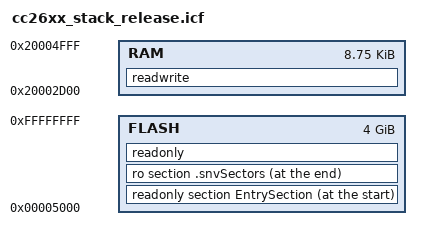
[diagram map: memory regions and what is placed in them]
/******************************************************************************

 @file  cc26xx_stack_release.icf

 @brief IAR ARM Linker Configuration File - BLE Stack

        Note: Code stack and heap are allocated by the Application/RTOS build.

        Imported Symbols
        Note: Linker defines are located in the IAR IDE project using
        --config_def in Options->Linker->Extra Options, or placed in
        Options->Linker-> Config->Configuration file symbol definitions.

        CCxxxx:             Device Name (e.g. CC2650). In order to define this
                            symbol, the tool chain requires that it be set to
                            a specific value, but in fact, the actual value does
                            not matter as it is not used in the linker control
                            file. The only way this symbol is used is based on
                            whether it is defined or not, not its actual value.
                            There are other linker symbols that do specifically
                            set their value to 1 to indicate R1, and 2 to
                            indicate R2, and these values are checked and do make
                            a difference. However, it would appear confusing if
                            the device name's value did not correspond to the
                            value set in other linker symbols. In order to avoid
                            this confusion, when the symbol is defined, it should
                            be set to the value of the device's ROM that it
                            corresponds so as to look and feel consistent. Please
                            note that a device name symbol should always be
                            defined to avoid side effects from default values
                            that may not be correct for the device being used.
        FLASH_ONLY_BUILD:   Build full BLE stack in flash only memory.
        FLASH_ROM_BUILD:    Build Flash portion of BLE stack to work with ROM
                            code.
        ROM_BUILD:          Build ROM portion of BLE stack.
        COMMON_ROM_BUILD:   Build of common ROM code.
        TEST_ROM_IN_FLASH:  Build ROM code in Flash memory to test.
        ICALL_STACK0_START: Start address of flash only and flash ROM builds.
        ICALL_RAM0_START:   Start address of RAM.

        Exported Symbols
        Note: Can be used as externs in C code.

        ROM_BASE_ADDR:        Location of start of ROM (where RT Init is
                              expected).
        RAM_BASE_ADDR:        Location of start of RAM (for ICall and JT
                              pointers).
        COMMON_RAM_BASE_ADDR: Location of start of RAM (for ICall and JT
                              pointers).
        PAGE_SIZE:            Size of Flash sector, in bytes.
        NUM_SNV_PAGES:        Number of sectors used for Simple NV.

 Group: WCS, BTS
 Target Device: cc13xx_cc26xx

 ******************************************************************************
 
 Copyright (c) 2013-2022, Texas Instruments Incorporated
 All rights reserved.

 Redistribution and use in source and binary forms, with or without
 modification, are permitted provided that the following conditions
 are met:

 *  Redistributions of source code must retain the above copyright
    notice, this list of conditions and the following disclaimer.

 *  Redistributions in binary form must reproduce the above copyright
    notice, this list of conditions and the following disclaimer in the
    documentation and/or other materials provided with the distribution.

 *  Neither the name of Texas Instruments Incorporated nor the names of
    its contributors may be used to endorse or promote products derived
    from this software without specific prior written permission.

 THIS SOFTWARE IS PROVIDED BY THE COPYRIGHT HOLDERS AND CONTRIBUTORS "AS IS"
 AND ANY EXPRESS OR IMPLIED WARRANTIES, INCLUDING, BUT NOT LIMITED TO,
 THE IMPLIED WARRANTIES OF MERCHANTABILITY AND FITNESS FOR A PARTICULAR
 PURPOSE ARE DISCLAIMED. IN NO EVENT SHALL THE COPYRIGHT OWNER OR
 CONTRIBUTORS BE LIABLE FOR ANY DIRECT, INDIRECT, INCIDENTAL, SPECIAL,
 EXEMPLARY, OR CONSEQUENTIAL DAMAGES (INCLUDING, BUT NOT LIMITED TO,
 PROCUREMENT OF SUBSTITUTE GOODS OR SERVICES; LOSS OF USE, DATA, OR PROFITS;
 OR BUSINESS INTERRUPTION) HOWEVER CAUSED AND ON ANY THEORY OF LIABILITY,
 WHETHER IN CONTRACT, STRICT LIABILITY, OR TORT (INCLUDING NEGLIGENCE OR
 OTHERWISE) ARISING IN ANY WAY OUT OF THE USE OF THIS SOFTWARE,
 EVEN IF ADVISED OF THE POSSIBILITY OF SUCH DAMAGE.

 ******************************************************************************
 
 
 *****************************************************************************/

////////////////////////////////////////////////////////////////////////////////
// Memory Sizes
////////////////////////////////////////////////////////////////////////////////

// isdefinedsymbol(CC2650) <- Do not delete used by the Boundary tool file parser
// isdefinedsymbol(CC2640) <- Do not delete used by the Boundary tool file parser
define symbol RAM_SIZE              = 0x00005000;  // 20K
define symbol FLASH_SIZE            = 0x00020000;  // 128K

////////////////////////////////////////////////////////////////////////////////
// Memory Definitions
////////////////////////////////////////////////////////////////////////////////

////////////////////////////////////////////////////////////////////////////////
// RAM
//
if ( isdefinedsymbol(FLASH_ONLY_BUILD) )
{
  if ( isdefinedsymbol(ICALL_RAM0_START) )
  {
    define symbol RAM_START         = ICALL_RAM0_START;
  }
  else // default
  {
    define symbol RAM_START         = 0x20002D00;
  }

  if ( isdefinedsymbol(CC2650) )
  {
    define symbol RAM_END           = 0x20004FFF;
  }
  else // default
  {
    define symbol RAM_END           = 0x20003FFF;
  }
}
else if ( isdefinedsymbol(ROM_BUILD) )
{
  if ( isdefinedsymbol(CC2650) )
  {
    define symbol RAM_START         = 0x200048E8;
    define symbol RAM_END           = 0x20004F2B;
  }
  else
  {
    define symbol RAM_START         = 0x20003300;
    define symbol RAM_END           = 0x20003FFF;
  }

  define symbol RAM_BASE_ADDR       = RAM_START;
  export symbol RAM_BASE_ADDR;
}
else if ( isdefinedsymbol(FLASH_ROM_BUILD) )
{
  if ( isdefinedsymbol(CC2650) )
  {
    if ( isdefinedsymbol(ICALL_RAM0_START) )
    {
      define symbol RAM_START       = ICALL_RAM0_START;
    }
    else
    {
      define symbol RAM_START       = 0x20002800;
    }
    define symbol RAM_END           = 0x200048E7;
  }
  else
  {
    if ( isdefinedsymbol(ICALL_RAM0_START) )
    {
      define symbol RAM_START       = ICALL_RAM0_START;
    }
    else
    {
      define symbol RAM_START       = 0x20002D00;
    }
    define symbol RAM_END           = 0x200031FF;
  }
}
else // unknown build
{
  define symbol RAM_START           = 0xFFFFFFFF;
  define symbol RAM_END             = 0xFFFFFFFF;
}

////////////////////////////////////////////////////////////////////////////////
// Flash
//
define symbol PAGE_SIZE             = 0x1000;
export symbol PAGE_SIZE;

define symbol NUM_RESERVED_PAGES    = 1;
define symbol RESERVED_SIZE         = (NUM_RESERVED_PAGES * PAGE_SIZE);

if ( isdefinedsymbol(FLASH_ONLY_BUILD) )
{
  if ( isdefinedsymbol(ICALL_STACK0_START) )
  {
    define symbol FLASH_START       = ICALL_STACK0_START;
  }
  else // default
  {
    define symbol FLASH_START       = 0x00005000;
  }

  define symbol FLASH_END           = FLASH_SIZE - RESERVED_SIZE - 1;
}
else if ( isdefinedsymbol(FLASH_ROM_BUILD) )
{
  if ( isdefinedsymbol(ICALL_STACK0_START) )
  {
    define symbol FLASH_START       = ICALL_STACK0_START;
  }
  else // default
  {
    define symbol FLASH_START       = 0x00005000;
  }

  if ( isdefinedsymbol(TEST_ROM_IN_FLASH) )
  {
    define symbol FLASH_END         = (ROM_START-1);
  }
  else // ROM code is in ROM memory
  {
    define symbol FLASH_END         = FLASH_SIZE - RESERVED_SIZE - 1;
  }
}
else // unknown build
{
  define symbol FLASH_START         = 0xFFFFFFFF;
  define symbol FLASH_END           = 0xFFFFFFFF;
}

//Entry section is set to the sector before SNV.
define symbol ENTRY_SECTION_START     = ((FLASH_END + 1) - PAGE_SIZE * 2);
define symbol ENTRY_SECTION_END       = (FLASH_END - PAGE_SIZE);
////////////////////////////////////////////////////////////////////////////////
// Memory Regions
////////////////////////////////////////////////////////////////////////////////

define memory mem with size = 4G;

define region FLASH = mem:[from FLASH_START to FLASH_END];
define region RAM   = mem:[from RAM_START   to RAM_END];
define region ENTRY_SECTION = mem:[from ENTRY_SECTION_START   to ENTRY_SECTION_END];

////////////////////////////////////////////////////////////////////////////////
// Memory Placement
////////////////////////////////////////////////////////////////////////////////

// Flash Software Entry Point
////////////////////////////////////////////////////////////////////////////////

if ( isdefinedsymbol(FLASH_ONLY_BUILD) || isdefinedsymbol(FLASH_ROM_BUILD) )
{
  place at start of FLASH { readonly section EntrySection };
//  place at start of ENTRY_SECTION { readonly section EntrySection };
}

place at end of FLASH { ro section .snvSectors };
place in FLASH { readonly };
place in RAM { readwrite };


////////////////////////////////////////////////////////////////////////////////
// Initialization
////////////////////////////////////////////////////////////////////////////////

  initialize by copy with packing = packbits { readwrite };

do not initialize
{
  section .noinit,
  section .stack,
};

////////////////////////////////////////////////////////////////////////////////
